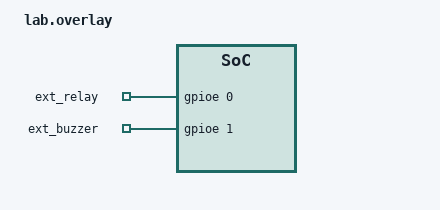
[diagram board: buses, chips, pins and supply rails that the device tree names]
/* Aliases used by the lab examples (same as docs/labs.md). */
/delete-node/ &st7920;

/ {
	ec_outputs {
		compatible = "gpio-leds";
		ext_relay: ext_relay { gpios = <&gpioe 0 GPIO_ACTIVE_HIGH>; };
		ext_buzzer: ext_buzzer { gpios = <&gpioe 1 GPIO_ACTIVE_HIGH>; };
	};

	aliases {
		out0 = &user_led;
		out1 = &ext_relay;
		out2 = &ext_buzzer;
		in0 = &user_btn;
	};
};

&gpioe { status = "okay"; };
